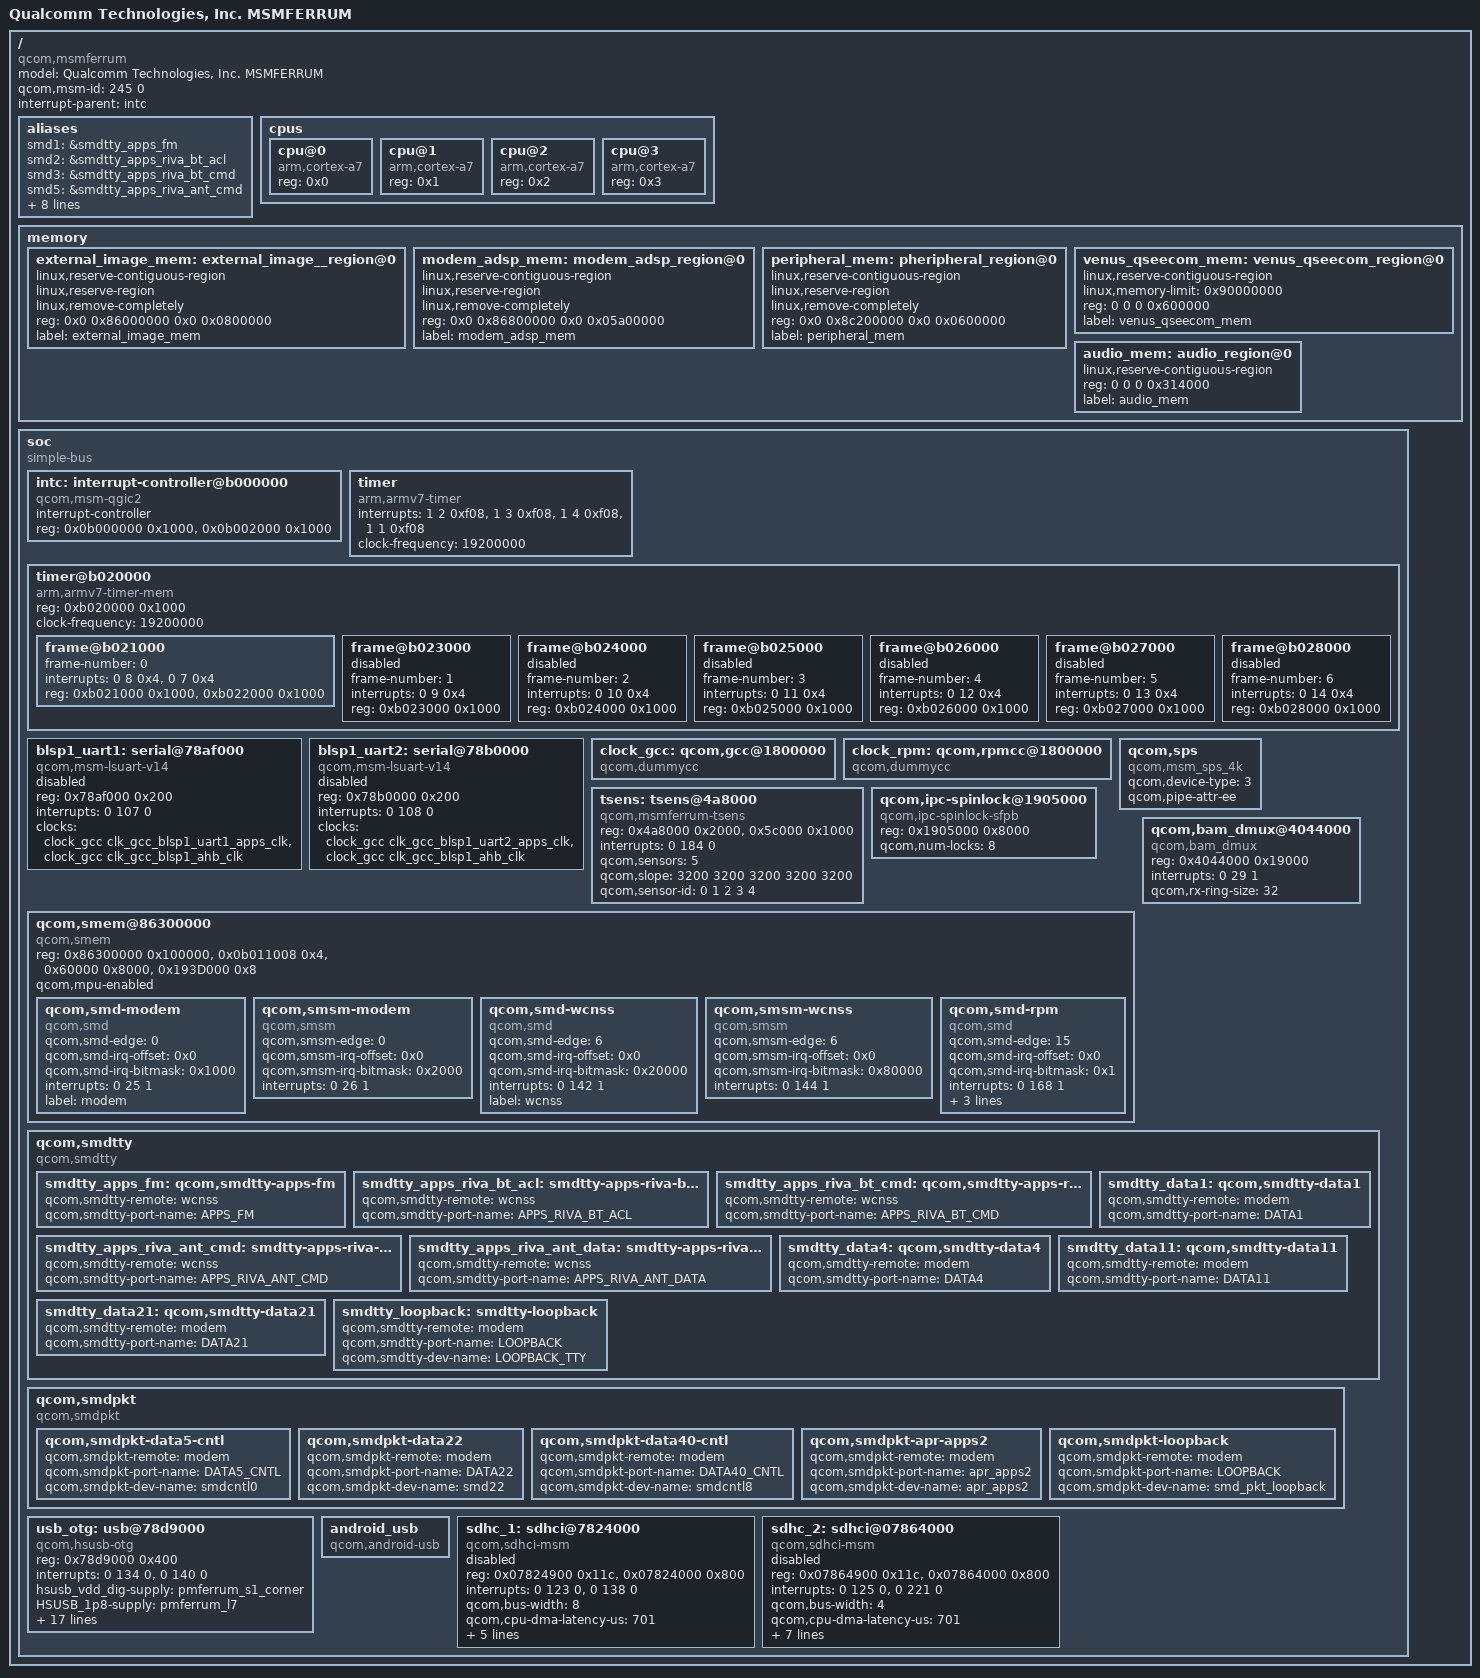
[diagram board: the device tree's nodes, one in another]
/* Copyright (c) 2014, The Linux Foundation. All rights reserved.
 *
 * This program is free software; you can redistribute it and/or modify
 * it under the terms of the GNU General Public License version 2 and
 * only version 2 as published by the Free Software Foundation.
 *
 * This program is distributed in the hope that it will be useful,
 * but WITHOUT ANY WARRANTY; without even the implied warranty of
 * MERCHANTABILITY or FITNESS FOR A PARTICULAR PURPOSE.  See the
 * GNU General Public License for more details.
 */

#include "skeleton64.dtsi"
#include <dt-bindings/clock/msm-clocks-ferrum.h>

/ {
	model = "Qualcomm Technologies, Inc. MSMFERRUM";
	compatible = "qcom,msmferrum";
	qcom,msm-id = <245 0>;
	interrupt-parent = <&intc>;

	aliases {
		/* smdtty devices */
		smd1 = &smdtty_apps_fm;
		smd2 = &smdtty_apps_riva_bt_acl;
		smd3 = &smdtty_apps_riva_bt_cmd;
		smd5 = &smdtty_apps_riva_ant_cmd;
		smd6 = &smdtty_apps_riva_ant_data;
		smd7 = &smdtty_data1;
		smd8 = &smdtty_data4;
		smd11 = &smdtty_data11;
		smd21 = &smdtty_data21;
		smd36 = &smdtty_loopback;

		sdhc1 = &sdhc_1; /* SDC1 eMMC slot */
		sdhc2 = &sdhc_2; /* SDC2 SD card slot */
	};

	cpus {
		#address-cells = <1>;
		#size-cells = <0>;
		cpu@0 {
			device_type = "cpu";
			compatible = "arm,cortex-a7";
			reg = <0x0>;
		};

		cpu@1 {
			device_type = "cpu";
			compatible = "arm,cortex-a7";
			reg = <0x1>;
		};

		cpu@2 {
			device_type = "cpu";
			compatible = "arm,cortex-a7";
			reg = <0x2>;
		};

		cpu@3 {
			device_type = "cpu";
			compatible = "arm,cortex-a7";
			reg = <0x3>;
		};
	};

	memory {
		#address-cells = <2>;
		#size-cells = <2>;

		external_image_mem: external_image__region@0 {
			linux,reserve-contiguous-region;
			linux,reserve-region;
			linux,remove-completely;
			reg = <0x0 0x86000000 0x0 0x0800000>;
			label = "external_image_mem";
		};

		modem_adsp_mem: modem_adsp_region@0 {
			linux,reserve-contiguous-region;
			linux,reserve-region;
			linux,remove-completely;
			reg = <0x0 0x86800000 0x0 0x05a00000>;
			label = "modem_adsp_mem";
		};

		peripheral_mem: pheripheral_region@0 {
			linux,reserve-contiguous-region;
			linux,reserve-region;
			linux,remove-completely;
			reg = <0x0 0x8c200000 0x0 0x0600000>;
			label = "peripheral_mem";
		};

		venus_qseecom_mem: venus_qseecom_region@0 {
			linux,reserve-contiguous-region;
			linux,memory-limit = <0x90000000>;
			reg = <0 0 0 0x600000>;
			label = "venus_qseecom_mem";
		};

		audio_mem: audio_region@0 {
			linux,reserve-contiguous-region;
			reg = <0 0 0 0x314000>;
			label = "audio_mem";
		};
	};

	soc: soc { };
};

#include "msmferrum-ion.dtsi"
#include "msmferrum-smp2p.dtsi"
#include "msmferrum-ipcrouter.dtsi"

&soc {
	#address-cells = <1>;
	#size-cells = <1>;
	ranges = <0 0 0 0xffffffff>;
	compatible = "simple-bus";

	intc: interrupt-controller@b000000 {
		compatible = "qcom,msm-qgic2";
		interrupt-controller;
		#interrupt-cells = <3>;
		reg = <0x0b000000 0x1000>,
		<0x0b002000 0x1000>;
	};

	timer {
		compatible = "arm,armv7-timer";
		interrupts = <1 2 0xf08>,
			     <1 3 0xf08>,
			     <1 4 0xf08>,
			     <1 1 0xf08>;
		clock-frequency = <19200000>;
	};

	timer@b020000 {
		#address-cells = <1>;
		#size-cells = <1>;
		ranges;
		compatible = "arm,armv7-timer-mem";
		reg = <0xb020000 0x1000>;
		clock-frequency = <19200000>;

		frame@b021000 {
			frame-number = <0>;
			interrupts = <0 8 0x4>,
				     <0 7 0x4>;
			reg = <0xb021000 0x1000>,
			      <0xb022000 0x1000>;
		};
		frame@b023000 {
			frame-number = <1>;
			interrupts = <0 9 0x4>;
			reg = <0xb023000 0x1000>;
			status = "disabled";
		};
		frame@b024000 {
			frame-number = <2>;
			interrupts = <0 10 0x4>;
			reg = <0xb024000 0x1000>;
			status = "disabled";
		};
		frame@b025000 {
			frame-number = <3>;
			interrupts = <0 11 0x4>;
			reg = <0xb025000 0x1000>;
			status = "disabled";
		};
		frame@b026000 {
			frame-number = <4>;
			interrupts = <0 12 0x4>;
			reg = <0xb026000 0x1000>;
			status = "disabled";
		};
		frame@b027000 {
			frame-number = <5>;
			interrupts = <0 13 0x4>;
			reg = <0xb027000 0x1000>;
			status = "disabled";
		};
		frame@b028000 {
			frame-number = <6>;
			interrupts = <0 14 0x4>;
			reg = <0xb028000 0x1000>;
			status = "disabled";
		};
	};

	blsp1_uart1: serial@78af000 {
		compatible = "qcom,msm-lsuart-v14";
		reg = <0x78af000 0x200>;
		interrupts = <0 107 0>;
		status = "disabled";
		clocks = <&clock_gcc clk_gcc_blsp1_uart1_apps_clk>,
			 <&clock_gcc clk_gcc_blsp1_ahb_clk>;
		clock-names = "core_clk", "iface_clk";
	};

	blsp1_uart2: serial@78b0000 {
		compatible = "qcom,msm-lsuart-v14";
		reg = <0x78b0000 0x200>;
		interrupts = <0 108 0>;
		status = "disabled";
		clocks = <&clock_gcc clk_gcc_blsp1_uart2_apps_clk>,
			 <&clock_gcc clk_gcc_blsp1_ahb_clk>;
		clock-names = "core_clk", "iface_clk";
	};

	clock_gcc: qcom,gcc@1800000 {
		compatible = "qcom,dummycc";
		#clock-cells = <1>;
	};

	clock_rpm: qcom,rpmcc@1800000 {
		compatible = "qcom,dummycc";
		#clock-cells = <1>;
	};

	qcom,sps {
		compatible = "qcom,msm_sps_4k";
		qcom,device-type = <3>;
		qcom,pipe-attr-ee;
	};

	tsens: tsens@4a8000 {
		compatible = "qcom,msmferrum-tsens";
		reg = <0x4a8000 0x2000>,
		      <0x5c000  0x1000>;
		reg-names = "tsens_physical", "tsens_eeprom_physical";
		interrupts = <0 184 0>;
		qcom,sensors = <5>;
		qcom,slope = <3200 3200 3200 3200 3200>;
		qcom,sensor-id = <0 1 2 3 4>;
	};

	qcom,ipc-spinlock@1905000 {
		compatible = "qcom,ipc-spinlock-sfpb";
		reg = <0x1905000 0x8000>;
		qcom,num-locks = <8>;
	};

	qcom,smem@86300000 {
		compatible = "qcom,smem";
		reg = <0x86300000 0x100000>,
			<0x0b011008 0x4>,
			<0x60000 0x8000>,
			<0x193D000 0x8>;
		reg-names = "smem", "irq-reg-base", "aux-mem1", "smem_targ_info_reg";
		qcom,mpu-enabled;

		qcom,smd-modem {
			compatible = "qcom,smd";
			qcom,smd-edge = <0>;
			qcom,smd-irq-offset = <0x0>;
			qcom,smd-irq-bitmask = <0x1000>;
			interrupts = <0 25 1>;
			label = "modem";
		};

		qcom,smsm-modem {
			compatible = "qcom,smsm";
			qcom,smsm-edge = <0>;
			qcom,smsm-irq-offset = <0x0>;
			qcom,smsm-irq-bitmask = <0x2000>;
			interrupts = <0 26 1>;
		};

		qcom,smd-wcnss {
			compatible = "qcom,smd";
			qcom,smd-edge = <6>;
			qcom,smd-irq-offset = <0x0>;
			qcom,smd-irq-bitmask = <0x20000>;
			interrupts = <0 142 1>;
			label = "wcnss";
		};

		qcom,smsm-wcnss {
			compatible = "qcom,smsm";
			qcom,smsm-edge = <6>;
			qcom,smsm-irq-offset = <0x0>;
			qcom,smsm-irq-bitmask = <0x80000>;
			interrupts = <0 144 1>;
		};

		qcom,smd-rpm {
			compatible = "qcom,smd";
			qcom,smd-edge = <15>;
			qcom,smd-irq-offset = <0x0>;
			qcom,smd-irq-bitmask = <0x1>;
			interrupts = <0 168 1>;
			label = "rpm";
			qcom,irq-no-suspend;
			qcom,not-loadable;
		};
	};

	qcom,bam_dmux@4044000 {
		compatible = "qcom,bam_dmux";
		reg = <0x4044000 0x19000>;
		interrupts = <0 29 1>;
		qcom,rx-ring-size = <32>;
	};

	qcom,smdtty {
		compatible = "qcom,smdtty";

		smdtty_apps_fm: qcom,smdtty-apps-fm {
			qcom,smdtty-remote = "wcnss";
			qcom,smdtty-port-name = "APPS_FM";
		};

		smdtty_apps_riva_bt_acl: smdtty-apps-riva-bt-acl {
			qcom,smdtty-remote = "wcnss";
			qcom,smdtty-port-name = "APPS_RIVA_BT_ACL";
		};

		smdtty_apps_riva_bt_cmd: qcom,smdtty-apps-riva-bt-cmd {
			qcom,smdtty-remote = "wcnss";
			qcom,smdtty-port-name = "APPS_RIVA_BT_CMD";
		};

		smdtty_apps_riva_ant_cmd: smdtty-apps-riva-ant-cmd {
			qcom,smdtty-remote = "wcnss";
			qcom,smdtty-port-name = "APPS_RIVA_ANT_CMD";
		};

		smdtty_apps_riva_ant_data: smdtty-apps-riva-ant-data {
			qcom,smdtty-remote = "wcnss";
			qcom,smdtty-port-name = "APPS_RIVA_ANT_DATA";
		};

		smdtty_data1: qcom,smdtty-data1 {
			qcom,smdtty-remote = "modem";
			qcom,smdtty-port-name = "DATA1";
		};

		smdtty_data4: qcom,smdtty-data4 {
			qcom,smdtty-remote = "modem";
			qcom,smdtty-port-name = "DATA4";
		};

		smdtty_data11: qcom,smdtty-data11 {
			qcom,smdtty-remote = "modem";
			qcom,smdtty-port-name = "DATA11";
		};

		smdtty_data21: qcom,smdtty-data21 {
			qcom,smdtty-remote = "modem";
			qcom,smdtty-port-name = "DATA21";
		};

		smdtty_loopback: smdtty-loopback {
			qcom,smdtty-remote = "modem";
			qcom,smdtty-port-name = "LOOPBACK";
			qcom,smdtty-dev-name = "LOOPBACK_TTY";
		};
	};

	qcom,smdpkt {
		compatible = "qcom,smdpkt";

		qcom,smdpkt-data5-cntl {
			qcom,smdpkt-remote = "modem";
			qcom,smdpkt-port-name = "DATA5_CNTL";
			qcom,smdpkt-dev-name = "smdcntl0";
		};

		qcom,smdpkt-data22 {
			qcom,smdpkt-remote = "modem";
			qcom,smdpkt-port-name = "DATA22";
			qcom,smdpkt-dev-name = "smd22";
		};

		qcom,smdpkt-data40-cntl {
			qcom,smdpkt-remote = "modem";
			qcom,smdpkt-port-name = "DATA40_CNTL";
			qcom,smdpkt-dev-name = "smdcntl8";
		};

		qcom,smdpkt-apr-apps2 {
			qcom,smdpkt-remote = "modem";
			qcom,smdpkt-port-name = "apr_apps2";
			qcom,smdpkt-dev-name = "apr_apps2";
		};

		qcom,smdpkt-loopback {
			qcom,smdpkt-remote = "modem";
			qcom,smdpkt-port-name = "LOOPBACK";
			qcom,smdpkt-dev-name = "smd_pkt_loopback";
		};
	};

	usb_otg: usb@78d9000 {
		compatible = "qcom,hsusb-otg";

		reg = <0x78d9000 0x400>;
		interrupts = <0 134 0>,<0 140 0>;
		interrupt-names = "core_irq", "async_irq";

		hsusb_vdd_dig-supply = <&pmferrum_s1_corner>;
		HSUSB_1p8-supply = <&pmferrum_l7>;
		HSUSB_3p3-supply = <&pmferrum_l13>;
		qcom,vdd-voltage-level = <1 5 7>;

		qcom,hsusb-otg-phy-init-seq =
			<0x44 0x80 0x6B 0x81 0x24 0x82 0x13 0x83 0xffffffff>;
		qcom,hsusb-otg-phy-type = <2>; /* SNPS 28nm Pico PHY */
		qcom,hsusb-otg-mode = <1>; /* DEVICE only */
		qcom,hsusb-otg-otg-control = <1>; /* PHY */
		qcom,dp-manual-pullup;

		qcom,msm-bus,name = "usb2";
		qcom,msm-bus,num-cases = <3>;
		qcom,msm-bus,num-paths = <1>;
		qcom,msm-bus,vectors-KBps =
				<87 512 0 0>,
				<87 512 60000 960000>,
				<87 512 6000  6000>;
		clocks = <&clock_gcc clk_gcc_usb_hs_ahb_clk>,
			 <&clock_gcc clk_gcc_usb_hs_system_clk>,
			 <&clock_gcc clk_gcc_usb2a_phy_sleep_clk>,
			 <&clock_rpm clk_xo_otg_clk>;
		clock-names = "iface_clk", "core_clk", "sleep_clk",
				"xo";
	};

	android_usb {
		compatible = "qcom,android-usb";
	};

	sdhc_1: sdhci@7824000 {
		compatible = "qcom,sdhci-msm";
		reg = <0x07824900 0x11c>, <0x07824000 0x800>;
		reg-names = "hc_mem", "core_mem";

		interrupts = <0 123 0>, <0 138 0>;
		interrupt-names = "hc_irq", "pwr_irq";

		qcom,bus-width = <8>;

		qcom,cpu-dma-latency-us = <701>;
		qcom,msm-bus,name = "sdhc1";
		qcom,msm-bus,num-cases = <8>;
		qcom,msm-bus,num-paths = <1>;

		clocks = <&clock_gcc clk_gcc_sdcc1_ahb_clk>,
			 <&clock_gcc clk_gcc_sdcc1_apps_clk>;
		clock-names = "iface_clk", "core_clk";

		status = "disabled";
	};

	sdhc_2: sdhci@07864000 {
		compatible = "qcom,sdhci-msm";
		reg = <0x07864900 0x11c>, <0x07864000 0x800>;
		reg-names = "hc_mem", "core_mem";

		interrupts = <0 125 0>, <0 221 0>;
		interrupt-names = "hc_irq", "pwr_irq";

		qcom,bus-width = <4>;

		qcom,cpu-dma-latency-us = <701>;
		qcom,msm-bus,name = "sdhc2";
		qcom,msm-bus,num-cases = <8>;
		qcom,msm-bus,num-paths = <1>;

		clocks = <&clock_gcc clk_gcc_sdcc2_ahb_clk>,
			 <&clock_gcc clk_gcc_sdcc2_apps_clk>;
		clock-names = "iface_clk", "core_clk";

		qcom,clk-rates = <400000 25000000 50000000 100000000 200000000>;

		status = "disabled";
	};
};

#include "msmferrum-regulator.dtsi"
